# STM32WLE5 register map
File version: 1.6
CPU: CM4 r0p1, little endian, MPU, no FPU, 4 interrupt priority bits
Registers are 32-bit, read-write, reset 0x0 unless marked. A register's access mark holds for its fields unless they carry their own. Offsets are from the block's base; [hi:lo] are bit positions; {n}, {i} and the like mark numbered series; 'fields as' and 'values as' point back to an identical list.

## EXTI — External interrupt/event controller
Base 0x58000800
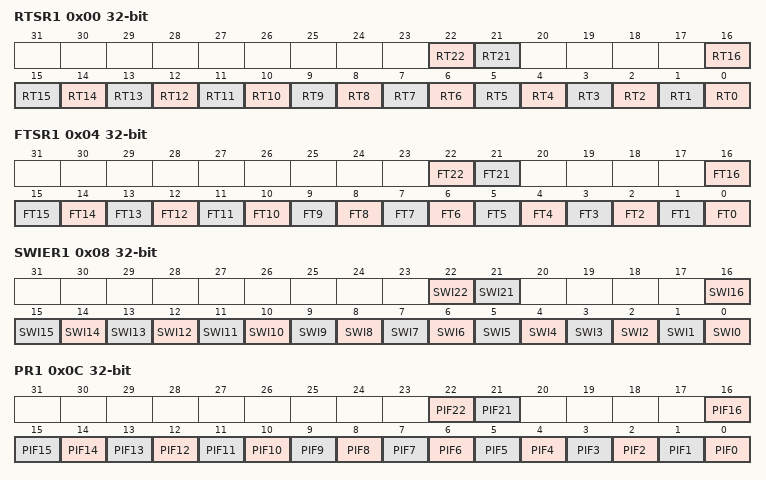
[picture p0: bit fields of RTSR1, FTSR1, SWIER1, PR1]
0x00 RTSR1 — rising trigger selection register
  [all] fields
    0=Disabled (Rising edge trigger is disabled); 1=Enabled (Rising edge trigger is enabled)
  [22] RT22 — Rising trigger event configuration bit of Configurable Event input
  [21] RT21 — Rising trigger event configuration bit of Configurable Event input
  [n] RT{n} (n=0..16) — Rising trigger event configuration bit of Configurable Event input
0x04 FTSR1 — falling trigger selection register
  [all] fields
    0=Disabled (Falling edge trigger is disabled); 1=Enabled (Falling edge trigger is enabled)
  [22] FT22 — Falling trigger event configuration bit of Configurable Event input
  [21] FT21 — Falling trigger event configuration bit of Configurable Event input
  [n] FT{n} (n=0..16) — Falling trigger event configuration bit of Configurable Event input
0x08 SWIER1 — software interrupt event register
  [all] fields
    on write: 1=Pend (Generates an interrupt request)
  [22] SWI22 — Software interrupt on event
  [21] SWI21 — Software interrupt on event
  [n] SWI{n} (n=0..16) — Software interrupt on event
0x0C PR1 — EXTI pending register
  [all] fields
    on read: 0=NotPending (No trigger request occurred); 1=Pending (Selected trigger request occurred) | on write: 1=Clears pending bit
  [22] PIF22 write-1-clears — Configurable event inputs Pending bit
  [21] PIF21 write-1-clears — Configurable event inputs Pending bit
  [n] PIF{n} write-1-clears (n=0..16) — Configurable event inputs Pending bit
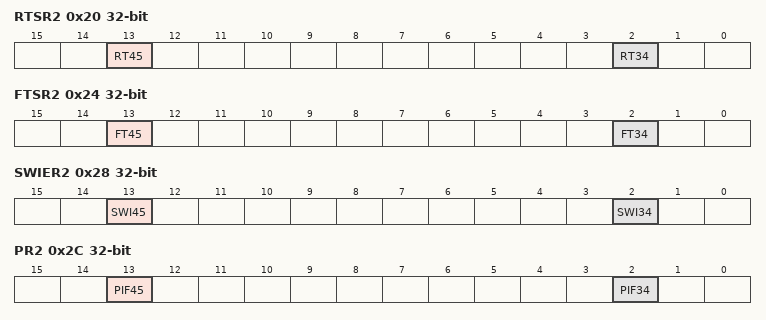
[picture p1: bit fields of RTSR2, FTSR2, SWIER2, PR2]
0x20 RTSR2 — rising trigger selection register
  [13] RT45 — Rising trigger event configuration bit of Configurable Event input
    values as the fields of RTSR1
  [2] RT34 — Rising trigger event configuration bit of Configurable Event input
    values as the fields of RTSR1
0x24 FTSR2 — falling trigger selection register
  [13] FT45 — Falling trigger event configuration bit of Configurable Event input
    values as the fields of FTSR1
  [2] FT34 — Falling trigger event configuration bit of Configurable Event input
    values as the fields of FTSR1
0x28 SWIER2 — software interrupt event register
  [13] SWI45 — Software interrupt on event 45
    on write: 1=Pend (Generates an interrupt request)
  [2] SWI34 — Software interrupt on event
    on write: 1=Pend (Generates an interrupt request)
0x2C PR2 — pending register
  [13] PIF45 write-1-clears — Configurable event inputs 45 Pending bit.
    values as the fields of PR1
  [2] PIF34 write-1-clears — Configurable event inputs 33 Pending bit.
    values as the fields of PR1
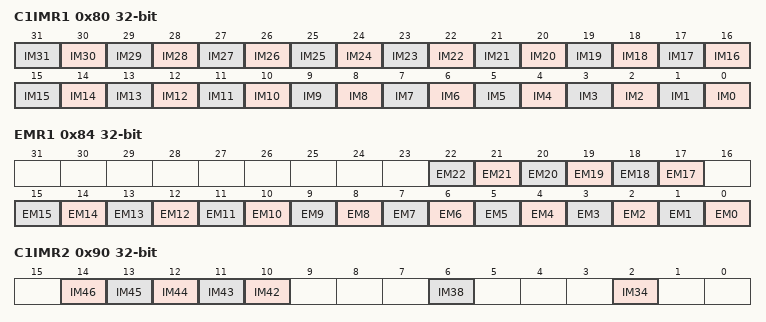
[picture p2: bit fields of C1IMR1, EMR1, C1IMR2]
0x80 C1IMR1 — interrupt mask register
  [all] fields
    0=Masked (Interrupt request line is masked); 1=Unmasked (Interrupt request line is unmasked)
  [n] IM{n} (n=0..31) — wakeup with interrupt Mask on event input
0x84 EMR1 — event mask register
  [all] fields
    0=Masked (Event request line is masked); 1=Unmasked (Event request line is unmasked)
  [n] EM{n} (n=17..22) — Wakeup with event generation Mask on Event input
  [n] EM{n} (n=0..15) — Wakeup with event generation Mask on Event input
0x90 C1IMR2 — interrupt mask register
  [all] fields
    values as the fields of C1IMR1
  [n-32] IM{n} (n=42..46) — CPUm Wakeup with interrupt Mask on Event input
  [6] IM38 — CPUm Wakeup with interrupt Mask on Event input
  [2] IM34 — CPUm Wakeup with interrupt Mask on Event input

## GPIOA — General-purpose I/Os
Base 0x48000000
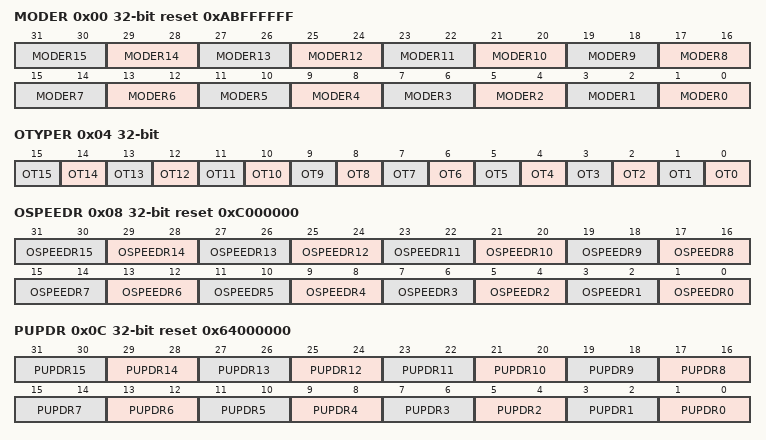
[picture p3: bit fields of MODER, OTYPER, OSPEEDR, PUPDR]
0x00 MODER reset 0xABFFFFFF — GPIO port mode register
  [2n+1:2n] MODER{n} (n=0..15) — Port x configuration pin {n}
    0=Input mode (reset state); 1=Output (General purpose output mode); 2=Alternate function mode; 3=Analog mode
0x04 OTYPER — GPIO port output type register
  [n] OT{n} (n=0..15) — Port x configuration pin {n}
    0=PushPull (Output push-pull (reset state)); 1=OpenDrain (Output open-drain)
0x08 OSPEEDR reset 0xC000000 — GPIO port output speed register
  [2n+1:2n] OSPEEDR{n} (n=0..15) — Port x configuration pin {n}
    0=LowSpeed; 1=MediumSpeed; 2=HighSpeed; 3=VeryHighSpeed
0x0C PUPDR reset 0x64000000 — GPIO port pull-up/pull-down register
  [2n+1:2n] PUPDR{n} (n=0..15) — Port x configuration pin {n}
    0=Floating (No pull-up, pull-down); 1=PullUp; 2=PullDown
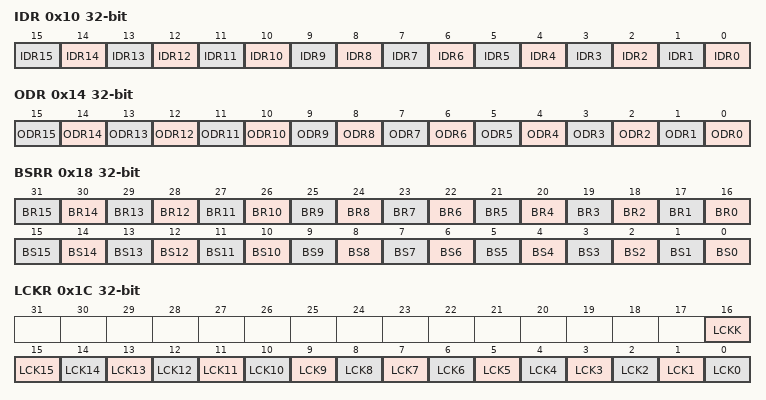
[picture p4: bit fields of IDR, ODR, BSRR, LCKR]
0x10 IDR ro — GPIO port input data register
  [n] IDR{n} (n=0..15) — Port input data pin {n}
    0=Low (Input is logic low); 1=High (Input is logic high)
0x14 ODR — GPIO port output data register
  [n] ODR{n} (n=0..15) — Port output data pin {n}
    0=Low (Set output to logic low); 1=High (Set output to logic high)
0x18 BSRR wo — GPIO port bit set/reset register
  [n+16] BR{n} (n=0..15) — Port x reset pin {n}
    1=Resets the corresponding ODRx bit
  [n] BS{n} (n=0..15) — Port x set pin {n}
    1=Set (Sets the corresponding ODRx bit)
0x1C LCKR — GPIO port configuration lock register
  [16] LCKK — Port x lock bit y (y= 0..15)
    0=NotActive (Port configuration lock key not active); 1=Active (Port configuration lock key active)
  [n] LCK{n} (n=0..15) — Port x lock pin {n}
    0=Unlocked (Port configuration not locked); 1=Locked (Port configuration locked)
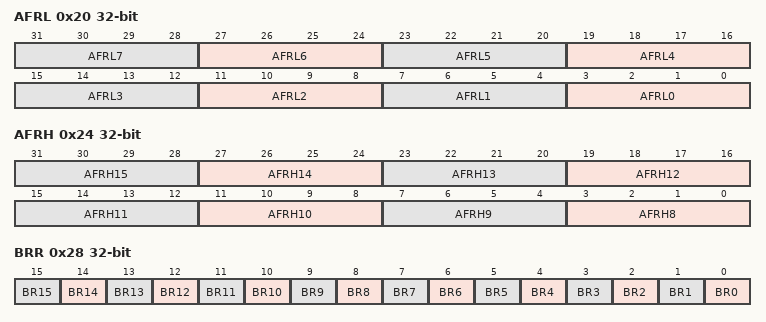
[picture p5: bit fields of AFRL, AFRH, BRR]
0x20 AFRL — GPIO alternate function low register
  [3:0] AFR{x} (x=L0,L1,L2,L3,L4,L5,L6,L7; step 4) — Alternate function selection for port x bit y (y = 0..7)
    {v}=AF{v} (v=0..15)
0x24 AFRH — GPIO alternate function high register
  [3:0] AFR{x} (x=H8,H9,H10,H11,H12,H13,H14,H15; step 4) — Alternate function selection for port x bit y (y = 8..15)
    {v}=AF{v} (v=0..15)
0x28 BRR — GPIO port bit reset register
  [n] BR{n} (n=0..15) — Port x reset pin {n}
    on write: 0=No action on the corresponding ODx bit; 1=Reset the ODx bit

## GPIOB — General-purpose I/Os
Base 0x48000400
Registers as GPIOA; these are added or differ:
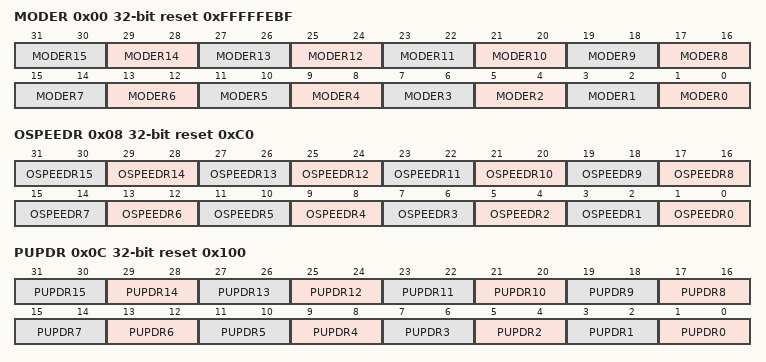
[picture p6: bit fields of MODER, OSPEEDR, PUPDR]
0x00 MODER reset 0xFFFFFEBF — GPIO port mode register
  [2n+1:2n] MODER{n} (n=0..15) — Port x configuration pin {n}
    0=Input mode (reset state); 1=Output (General purpose output mode); 2=Alternate function mode; 3=Analog mode
0x08 OSPEEDR reset 0xC0 — GPIO port output speed register
  [2n+1:2n] OSPEEDR{n} (n=0..15) — Port x configuration pin {n}
    0=LowSpeed; 1=MediumSpeed; 2=HighSpeed; 3=VeryHighSpeed
0x0C PUPDR reset 0x100 — GPIO port pull-up/pull-down register
  [2n+1:2n] PUPDR{n} (n=0..15) — Port x configuration pin {n}
    0=Floating (No pull-up, pull-down); 1=PullUp; 2=PullDown
